# bcm2711_lpa register map
Vendor: BROADCOM; Series: BCM2711; File version: A
CPU: CA72 r0p0, little endian, MPU, FPU, 2 interrupt priority bits
Registers are 32-bit, read-write, reset 0x0 unless marked. A register's access mark holds for its fields unless they carry their own. Offsets are from the block's base; [hi:lo] are bit positions; lines under a group give offsets from that group; {n}, {i} and the like mark numbered series; 'fields as' and 'values as' point back to an identical list.

## GIC_DIST — ARM GIC-400 Generic Interrupt Controller Distributor
Base 0xFF841000
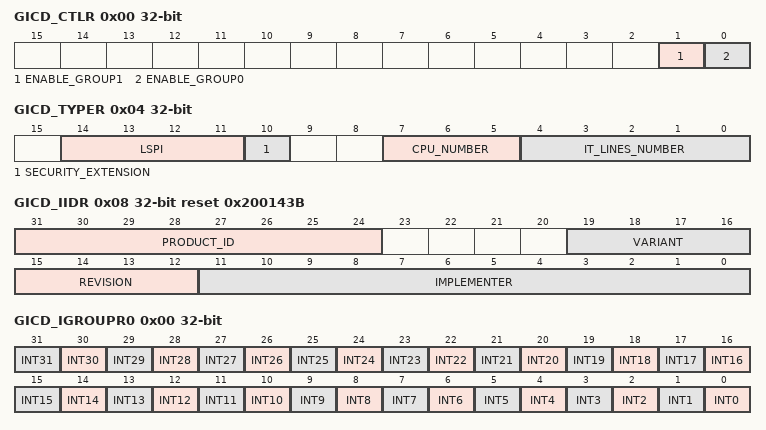
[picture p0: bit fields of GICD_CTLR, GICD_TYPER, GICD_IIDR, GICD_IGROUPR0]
0x00 GICD_CTLR — Distributor Control Register
  [1] ENABLE_GROUP1 — Enable group 1 interrupts
  [0] ENABLE_GROUP0 — Enable group 0 interrupts
0x04 GICD_TYPER ro — Interrupt Controller Type Register
  [14:11] LSPI — Lockable SPI count
  [10] SECURITY_EXTENSION — Security extension implemented
  [7:5] CPU_NUMBER
  [4:0] IT_LINES_NUMBER — Interrupt line number
0x08 GICD_IIDR ro reset 0x200143B — Distributor Implementer Identification Register
  [31:24] PRODUCT_ID, [19:16] VARIANT, [15:12] REVISION, [11:0] IMPLEMENTER
0x80 GICD_IGROUPR group — Interrupt Group Registers
  0x00 GICD_IGROUPR0 — Interrupt Group
    [n] INT{n} (n=0..31) — Interrupt {n}
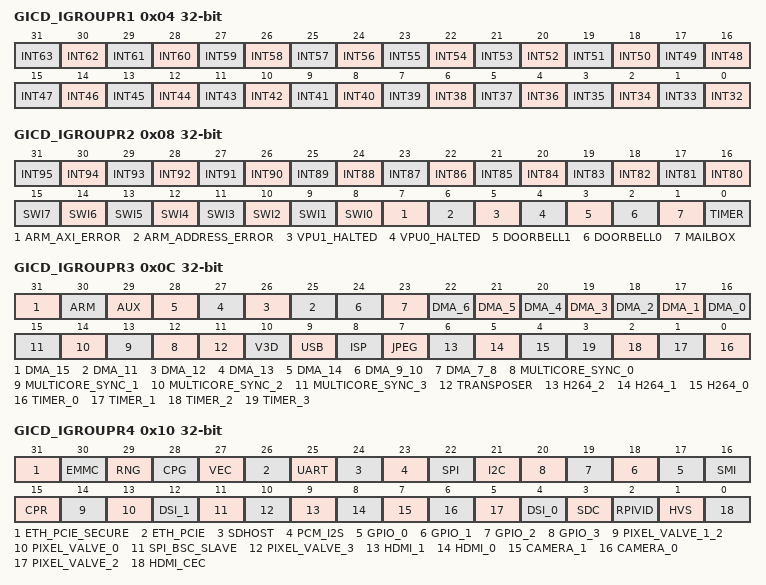
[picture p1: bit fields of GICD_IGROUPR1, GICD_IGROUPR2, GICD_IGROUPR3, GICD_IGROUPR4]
  0x04 GICD_IGROUPR1 — Interrupt Group
    [n-32] INT{n} (n=32..63) — Interrupt {n}
  0x08 GICD_IGROUPR2 — Interrupt Group
    [n-64] INT{n} (n=80..95) — Interrupt {n}
    [n+8] SWI{n} (n=0..7) — Software interrupt {n}
    [7] ARM_AXI_ERROR
    [6] ARM_ADDRESS_ERROR
    [5] VPU1_HALTED
    [4] VPU0_HALTED
    [3] DOORBELL1
    [2] DOORBELL0
    [1] MAILBOX
    [0] TIMER — ARMC Timer
  0x0C GICD_IGROUPR3 — Interrupt Group
    [31] DMA_15
    [30] ARM
    [29] AUX — OR of UART1, SPI1 and SPI2
    [n+14] DMA_{n} (n=11..14)
    [24] DMA_9_10 — OR of DMA 9 and 10
    [23] DMA_7_8 — OR of DMA 7 and 8
    [n+16] DMA_{n} (n=0..6)
    [n+12] MULTICORE_SYNC_{n} (n=0..3)
    [11] TRANSPOSER
    [10] V3D
    [9] USB
    [8] ISP
    [7] JPEG
    [6] H264_2
    [5] H264_1
    [4] H264_0
    [n] TIMER_{n} (n=0..3)
  0x10 GICD_IGROUPR4 — Interrupt Group
    [31] ETH_PCIE_SECURE
    [30] EMMC — OR of EMMC and EMMC2
    [29] RNG
    [28] CPG
    [27] VEC
    [26] ETH_PCIE — OR of all ETH_PCIe L2
    [25] UART — OR of all PL011 UARTs
    [24] SDHOST
    [23] PCM_I2S
    [22] SPI — OR of all SPI
    [21] I2C — OR of all I2C
    [n+17] GPIO_{n} (n=0..3)
    [16] SMI
    [15] CPR
    [14] PIXEL_VALVE_1_2 — OR of Pixel Valve 1 and 2
    [13] PIXEL_VALVE_0
    [12] DSI_1
    [11] SPI_BSC_SLAVE
    [10] PIXEL_VALVE_3
    [9] HDMI_1
    [8] HDMI_0
    [7] CAMERA_1
    [6] CAMERA_0
    [5] PIXEL_VALVE_2
    [4] DSI_0
    [3] SDC
    [2] RPIVID
    [1] HVS
    [0] HDMI_CEC
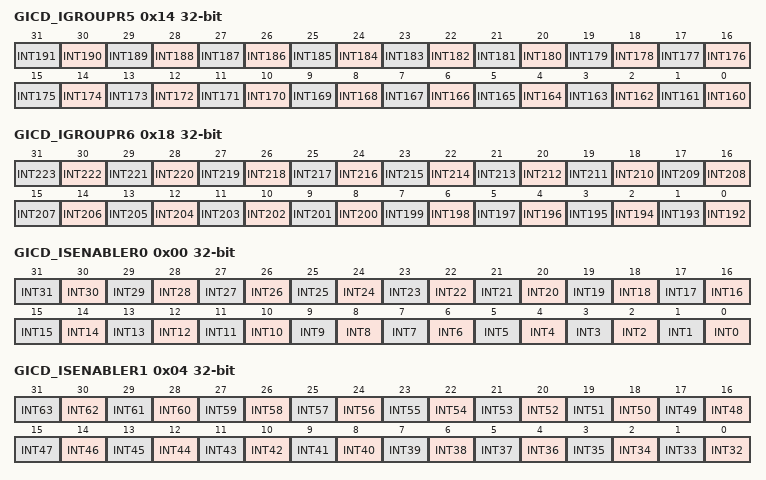
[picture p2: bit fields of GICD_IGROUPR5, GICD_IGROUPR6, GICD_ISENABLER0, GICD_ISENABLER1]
  0x14 GICD_IGROUPR5 — Interrupt Group
    [n-160] INT{n} (n=160..191) — Interrupt {n}
  0x18 GICD_IGROUPR6 — Interrupt Group
    [n-192] INT{n} (n=192..223) — Interrupt {n}
0x100 GICD_ISENABLER group — Interrupt Set-Enable Registers
  0x00 GICD_ISENABLER0 write-1-sets — Interrupt Set-Enable
    [n] INT{n} (n=0..31) — Interrupt {n}
  0x04 GICD_ISENABLER1 write-1-sets — Interrupt Set-Enable
    [n-32] INT{n} (n=32..63) — Interrupt {n}
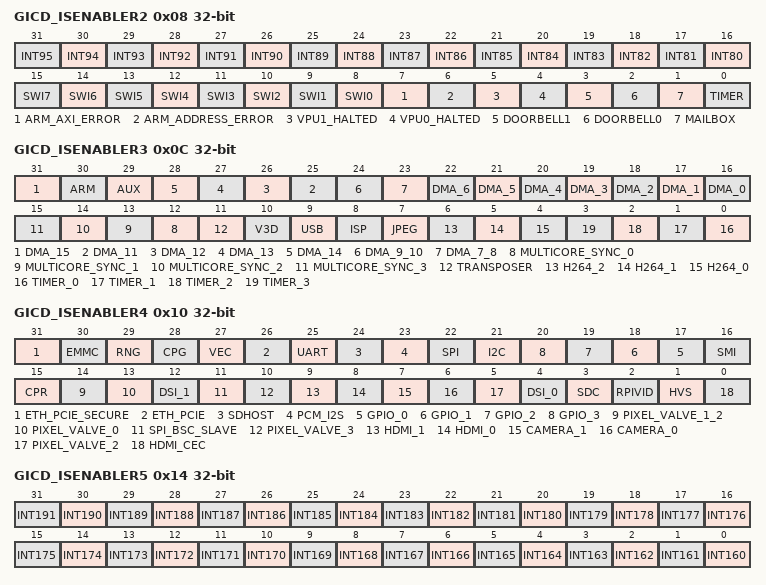
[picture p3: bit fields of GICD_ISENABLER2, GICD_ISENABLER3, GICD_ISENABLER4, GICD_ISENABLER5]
  0x08 GICD_ISENABLER2 write-1-sets — Interrupt Set-Enable
    fields as GICD_IGROUPR.GICD_IGROUPR2
  0x0C GICD_ISENABLER3 write-1-sets — Interrupt Set-Enable
    fields as GICD_IGROUPR.GICD_IGROUPR3
  0x10 GICD_ISENABLER4 write-1-sets — Interrupt Set-Enable
    fields as GICD_IGROUPR.GICD_IGROUPR4
  0x14 GICD_ISENABLER5 write-1-sets — Interrupt Set-Enable
    [n-160] INT{n} (n=160..191) — Interrupt {n}
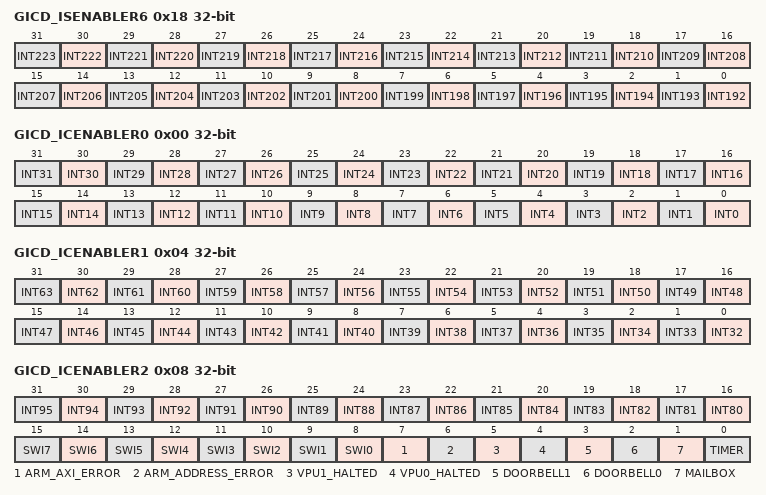
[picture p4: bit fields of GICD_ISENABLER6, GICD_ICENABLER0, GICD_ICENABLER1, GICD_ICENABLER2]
  0x18 GICD_ISENABLER6 write-1-sets — Interrupt Set-Enable
    [n-192] INT{n} (n=192..223) — Interrupt {n}
0x180 GICD_ICENABLER group — Interrupt Clear-Enable Registers
  0x00 GICD_ICENABLER0 write-1-clears — Interrupt Clear-Enable
    [n] INT{n} (n=0..31) — Interrupt {n}
  0x04 GICD_ICENABLER1 write-1-clears — Interrupt Clear-Enable
    [n-32] INT{n} (n=32..63) — Interrupt {n}
  0x08 GICD_ICENABLER2 write-1-clears — Interrupt Clear-Enable
    fields as GICD_IGROUPR.GICD_IGROUPR2
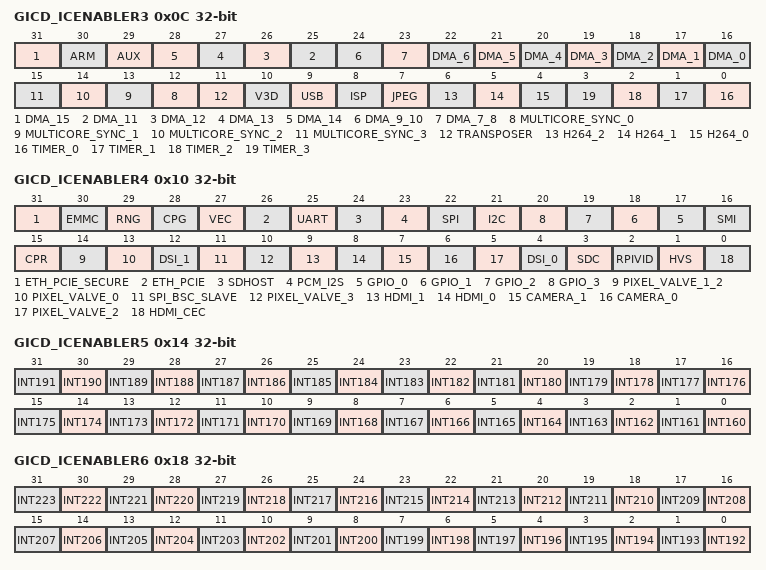
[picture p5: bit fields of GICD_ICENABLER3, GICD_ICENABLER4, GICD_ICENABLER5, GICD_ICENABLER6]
  0x0C GICD_ICENABLER3 write-1-clears — Interrupt Clear-Enable
    fields as GICD_IGROUPR.GICD_IGROUPR3
  0x10 GICD_ICENABLER4 write-1-clears — Interrupt Clear-Enable
    fields as GICD_IGROUPR.GICD_IGROUPR4
  0x14 GICD_ICENABLER5 write-1-clears — Interrupt Clear-Enable
    [n-160] INT{n} (n=160..191) — Interrupt {n}
  0x18 GICD_ICENABLER6 write-1-clears — Interrupt Clear-Enable
    [n-192] INT{n} (n=192..223) — Interrupt {n}
0x200 GICD_ISPENDR group — Interrupt Set-Pending Registers
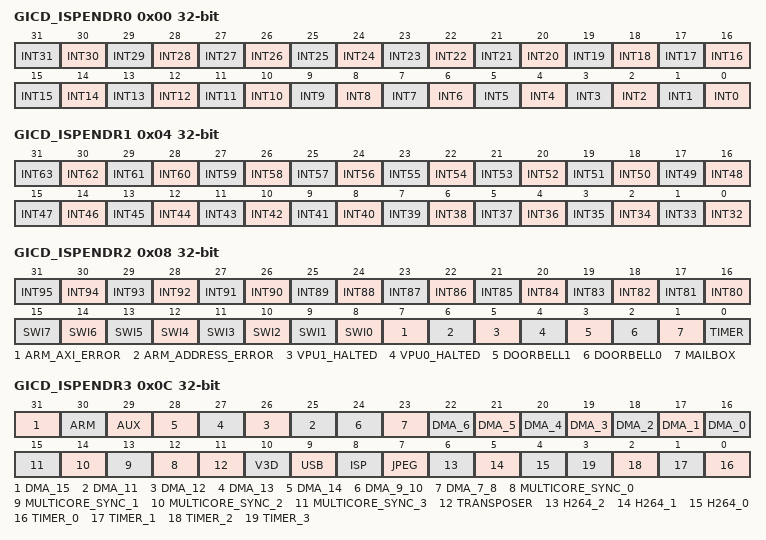
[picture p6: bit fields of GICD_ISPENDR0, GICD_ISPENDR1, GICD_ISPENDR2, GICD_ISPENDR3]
  0x00 GICD_ISPENDR0 write-1-sets — Interrupt Set-Pending
    [n] INT{n} (n=0..31) — Interrupt {n}
  0x04 GICD_ISPENDR1 write-1-sets — Interrupt Set-Pending
    [n-32] INT{n} (n=32..63) — Interrupt {n}
  0x08 GICD_ISPENDR2 write-1-sets — Interrupt Set-Pending
    fields as GICD_IGROUPR.GICD_IGROUPR2
  0x0C GICD_ISPENDR3 write-1-sets — Interrupt Set-Pending
    fields as GICD_IGROUPR.GICD_IGROUPR3
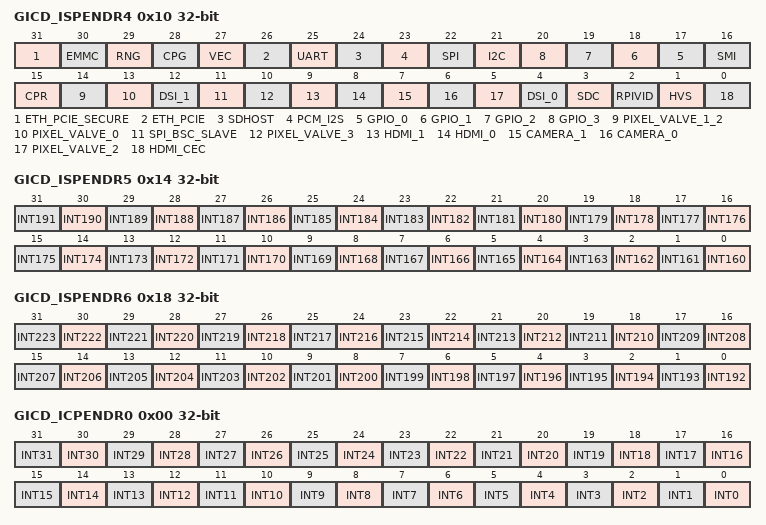
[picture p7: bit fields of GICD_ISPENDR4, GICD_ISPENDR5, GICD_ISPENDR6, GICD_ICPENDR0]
  0x10 GICD_ISPENDR4 write-1-sets — Interrupt Set-Pending
    fields as GICD_IGROUPR.GICD_IGROUPR4
  0x14 GICD_ISPENDR5 write-1-sets — Interrupt Set-Pending
    [n-160] INT{n} (n=160..191) — Interrupt {n}
  0x18 GICD_ISPENDR6 write-1-sets — Interrupt Set-Pending
    [n-192] INT{n} (n=192..223) — Interrupt {n}
0x280 GICD_ICPENDR group — Interrupt Clear-Pending Registers
  0x00 GICD_ICPENDR0 write-1-clears — Interrupt Clear-Pending
    [n] INT{n} (n=0..31) — Interrupt {n}
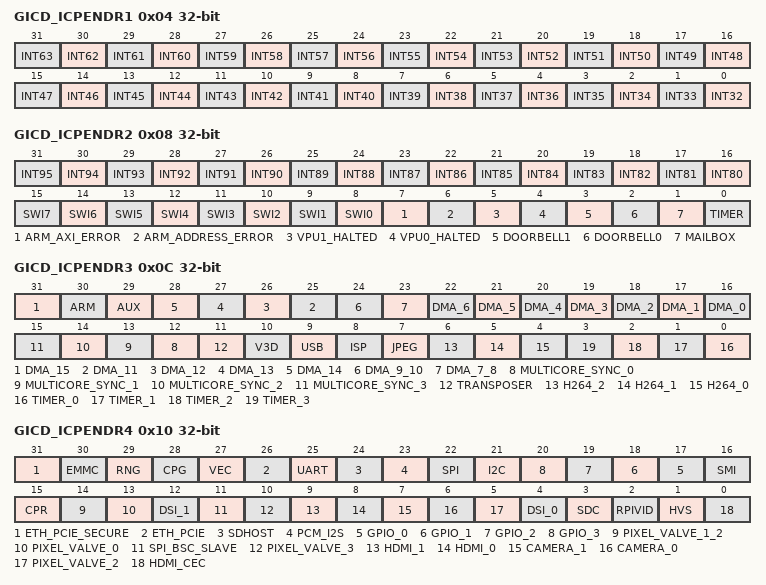
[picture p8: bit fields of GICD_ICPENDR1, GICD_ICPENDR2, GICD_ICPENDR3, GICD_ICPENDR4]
  0x04 GICD_ICPENDR1 write-1-clears — Interrupt Clear-Pending
    [n-32] INT{n} (n=32..63) — Interrupt {n}
  0x08 GICD_ICPENDR2 write-1-clears — Interrupt Clear-Pending
    fields as GICD_IGROUPR.GICD_IGROUPR2
  0x0C GICD_ICPENDR3 write-1-clears — Interrupt Clear-Pending
    fields as GICD_IGROUPR.GICD_IGROUPR3
  0x10 GICD_ICPENDR4 write-1-clears — Interrupt Clear-Pending
    fields as GICD_IGROUPR.GICD_IGROUPR4
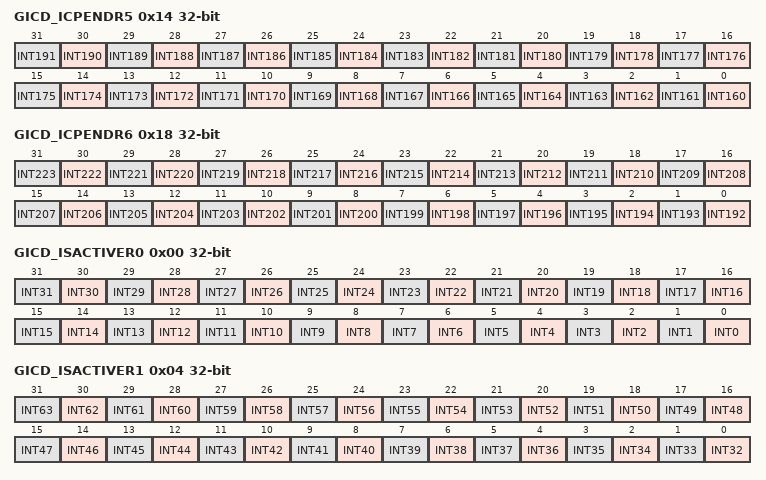
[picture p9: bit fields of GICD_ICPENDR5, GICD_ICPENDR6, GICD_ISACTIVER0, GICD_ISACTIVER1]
  0x14 GICD_ICPENDR5 write-1-clears — Interrupt Clear-Pending
    [n-160] INT{n} (n=160..191) — Interrupt {n}
  0x18 GICD_ICPENDR6 write-1-clears — Interrupt Clear-Pending
    [n-192] INT{n} (n=192..223) — Interrupt {n}
0x300 GICD_ISACTIVER group — Interrupt Set-Active Registers
  0x00 GICD_ISACTIVER0 write-1-sets — Interrupt Set-Active
    [n] INT{n} (n=0..31) — Interrupt {n}
  0x04 GICD_ISACTIVER1 write-1-sets — Interrupt Set-Active
    [n-32] INT{n} (n=32..63) — Interrupt {n}
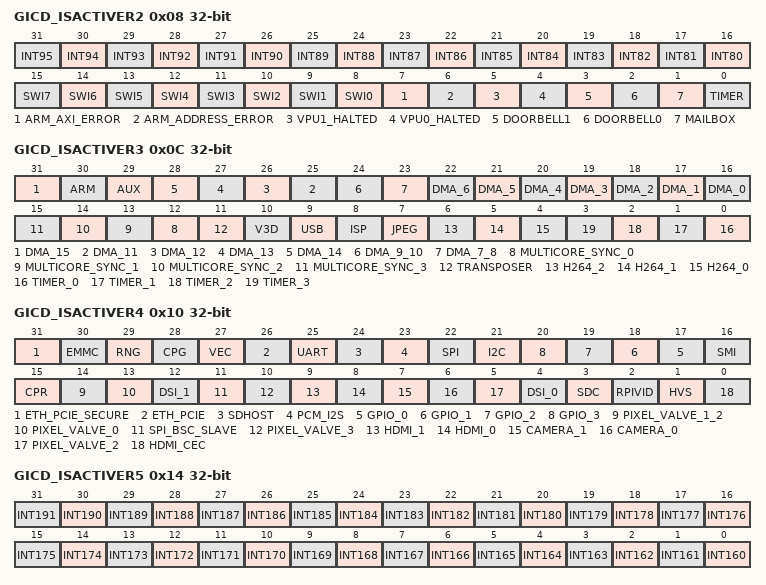
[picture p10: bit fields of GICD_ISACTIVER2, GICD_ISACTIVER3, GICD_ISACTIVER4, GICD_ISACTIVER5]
  0x08 GICD_ISACTIVER2 write-1-sets — Interrupt Set-Active
    fields as GICD_IGROUPR.GICD_IGROUPR2
  0x0C GICD_ISACTIVER3 write-1-sets — Interrupt Set-Active
    fields as GICD_IGROUPR.GICD_IGROUPR3
  0x10 GICD_ISACTIVER4 write-1-sets — Interrupt Set-Active
    fields as GICD_IGROUPR.GICD_IGROUPR4
  0x14 GICD_ISACTIVER5 write-1-sets — Interrupt Set-Active
    [n-160] INT{n} (n=160..191) — Interrupt {n}
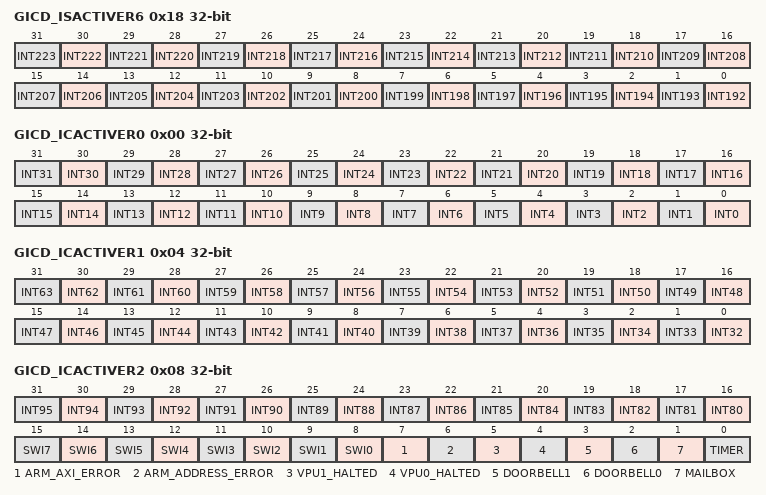
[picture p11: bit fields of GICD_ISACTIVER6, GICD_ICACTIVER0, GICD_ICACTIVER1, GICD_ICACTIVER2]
  0x18 GICD_ISACTIVER6 write-1-sets — Interrupt Set-Active
    [n-192] INT{n} (n=192..223) — Interrupt {n}
0x380 GICD_ICACTIVER group — Interrupt Clear-Active Registers
  0x00 GICD_ICACTIVER0 write-1-clears — Interrupt Clear-Active
    [n] INT{n} (n=0..31) — Interrupt {n}
  0x04 GICD_ICACTIVER1 write-1-clears — Interrupt Clear-Active
    [n-32] INT{n} (n=32..63) — Interrupt {n}
  0x08 GICD_ICACTIVER2 write-1-clears — Interrupt Clear-Active
    fields as GICD_IGROUPR.GICD_IGROUPR2
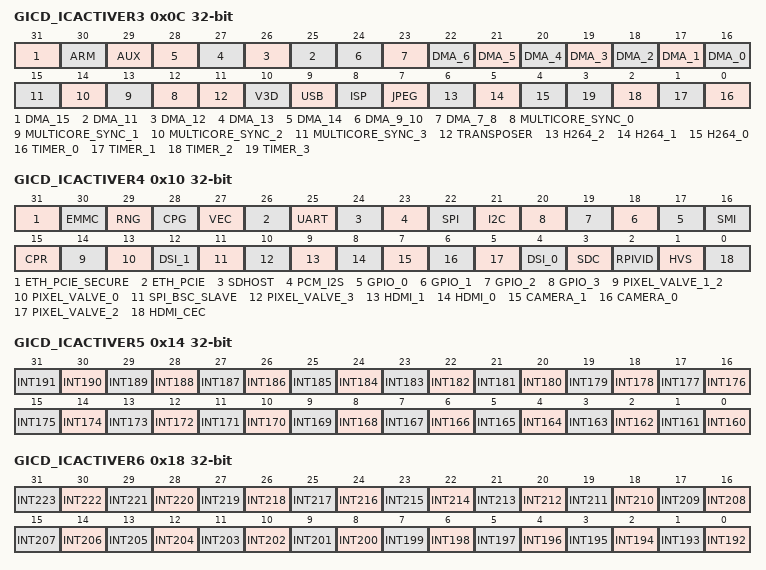
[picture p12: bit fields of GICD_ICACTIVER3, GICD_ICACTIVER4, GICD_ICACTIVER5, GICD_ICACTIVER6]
  0x0C GICD_ICACTIVER3 write-1-clears — Interrupt Clear-Active
    fields as GICD_IGROUPR.GICD_IGROUPR3
  0x10 GICD_ICACTIVER4 write-1-clears — Interrupt Clear-Active
    fields as GICD_IGROUPR.GICD_IGROUPR4
  0x14 GICD_ICACTIVER5 write-1-clears — Interrupt Clear-Active
    [n-160] INT{n} (n=160..191) — Interrupt {n}
  0x18 GICD_ICACTIVER6 write-1-clears — Interrupt Clear-Active
    [n-192] INT{n} (n=192..223) — Interrupt {n}
0x400 GICD_IPRIORITYR group — Interrupt Priority
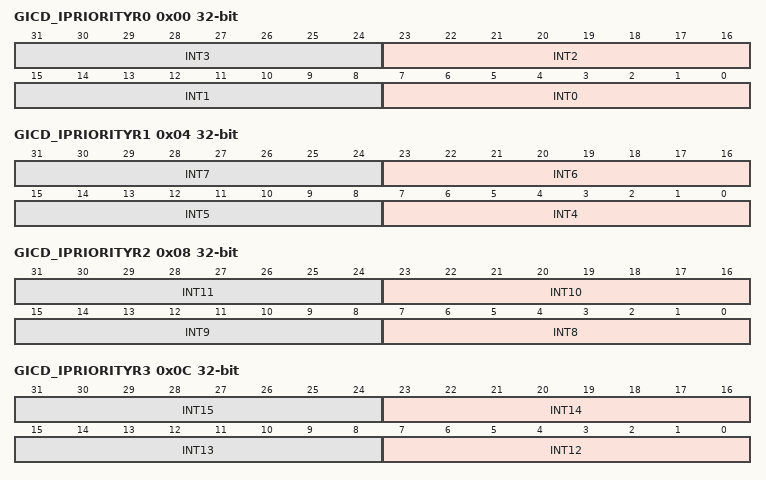
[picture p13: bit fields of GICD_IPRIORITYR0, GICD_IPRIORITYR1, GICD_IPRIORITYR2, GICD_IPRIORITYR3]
  0x00 GICD_IPRIORITYR0 — Interrupt Priority 0 - 3 (Lower is first)
    [8n+7:8n] INT{n} (n=0..3) — Interrupt {n}
  0x04 GICD_IPRIORITYR1 — Interrupt Priority 4 - 7 (Lower is first)
    [8n-25:8n-32] INT{n} (n=4..7) — Interrupt {n}
  0x08 GICD_IPRIORITYR2 — Interrupt Priority 8 - 11 (Lower is first)
    [8n-57:8n-64] INT{n} (n=8..11) — Interrupt {n}
  0x0C GICD_IPRIORITYR3 — Interrupt Priority 12 - 15 (Lower is first)
    [8n-89:8n-96] INT{n} (n=12..15) — Interrupt {n}
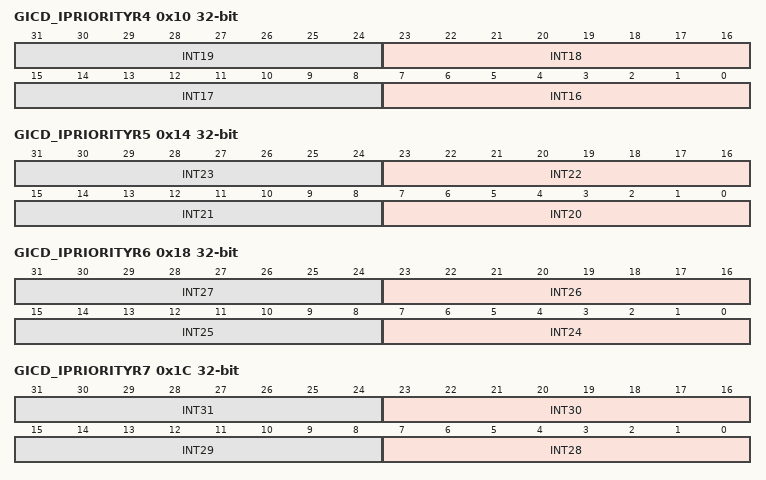
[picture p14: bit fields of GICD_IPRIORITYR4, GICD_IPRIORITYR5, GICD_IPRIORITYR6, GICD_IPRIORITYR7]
  0x10 GICD_IPRIORITYR4 — Interrupt Priority 16 - 19 (Lower is first)
    [8n-121:8n-128] INT{n} (n=16..19) — Interrupt {n}
  0x14 GICD_IPRIORITYR5 — Interrupt Priority 20 - 23 (Lower is first)
    [8n-153:8n-160] INT{n} (n=20..23) — Interrupt {n}
  0x18 GICD_IPRIORITYR6 — Interrupt Priority 24 - 27 (Lower is first)
    [8n-185:8n-192] INT{n} (n=24..27) — Interrupt {n}
  0x1C GICD_IPRIORITYR7 — Interrupt Priority 28 - 31 (Lower is first)
    [8n-217:8n-224] INT{n} (n=28..31) — Interrupt {n}
  0x20 GICD_IPRIORITYR8 — Interrupt Priority 32 - 35 (Lower is first)
    [8n-249:8n-256] INT{n} (n=32..35) — Interrupt {n}
  0x24 GICD_IPRIORITYR9 — Interrupt Priority 36 - 39 (Lower is first)
    [8n-281:8n-288] INT{n} (n=36..39) — Interrupt {n}
  0x28 GICD_IPRIORITYR10 — Interrupt Priority 40 - 43 (Lower is first)
    [8n-313:8n-320] INT{n} (n=40..43) — Interrupt {n}
  0x2C GICD_IPRIORITYR11 — Interrupt Priority 44 - 47 (Lower is first)
    [8n-345:8n-352] INT{n} (n=44..47) — Interrupt {n}
  0x30 GICD_IPRIORITYR12 — Interrupt Priority 48 - 51 (Lower is first)
    [8n-377:8n-384] INT{n} (n=48..51) — Interrupt {n}
  0x34 GICD_IPRIORITYR13 — Interrupt Priority 52 - 55 (Lower is first)
    [8n-409:8n-416] INT{n} (n=52..55) — Interrupt {n}
  0x38 GICD_IPRIORITYR14 — Interrupt Priority 56 - 59 (Lower is first)
    [8n-441:8n-448] INT{n} (n=56..59) — Interrupt {n}
  0x3C GICD_IPRIORITYR15 — Interrupt Priority 60 - 63 (Lower is first)
    [8n-473:8n-480] INT{n} (n=60..63) — Interrupt {n}
  0x40 GICD_IPRIORITYR16 — Interrupt Priority 64 - 67 (Lower is first)
    [31:24] DOORBELL1
    [23:16] DOORBELL0
    [15:8] MAILBOX
    [7:0] TIMER — ARMC Timer
  0x44 GICD_IPRIORITYR17 — Interrupt Priority 68 - 71 (Lower is first)
    [31:24] ARM_AXI_ERROR, [23:16] ARM_ADDRESS_ERROR, [15:8] VPU1_HALTED, [7:0] VPU0_HALTED
  0x48 GICD_IPRIORITYR18 — Interrupt Priority 72 - 75 (Lower is first)
    [8n+7:8n] SWI{n} (n=0..3) — Software interrupt {n}
  0x4C GICD_IPRIORITYR19 — Interrupt Priority 76 - 79 (Lower is first)
    [8n-25:8n-32] SWI{n} (n=4..7) — Software interrupt {n}
  0x50 GICD_IPRIORITYR20 — Interrupt Priority 80 - 83 (Lower is first)
    [8n-633:8n-640] INT{n} (n=80..83) — Interrupt {n}
  0x54 GICD_IPRIORITYR21 — Interrupt Priority 84 - 87 (Lower is first)
    [8n-665:8n-672] INT{n} (n=84..87) — Interrupt {n}
  0x58 GICD_IPRIORITYR22 — Interrupt Priority 88 - 91 (Lower is first)
    [8n-697:8n-704] INT{n} (n=88..91) — Interrupt {n}
  0x5C GICD_IPRIORITYR23 — Interrupt Priority 92 - 95 (Lower is first)
    [8n-729:8n-736] INT{n} (n=92..95) — Interrupt {n}
  0x60 GICD_IPRIORITYR24 — Interrupt Priority 96 - 99 (Lower is first)
    [8n+7:8n] TIMER_{n} (n=0..3)
  0x64 GICD_IPRIORITYR25 — Interrupt Priority 100 - 103 (Lower is first)
    [31:24] JPEG, [23:16] H264_2, [15:8] H264_1, [7:0] H264_0
  0x68 GICD_IPRIORITYR26 — Interrupt Priority 104 - 107 (Lower is first)
    [31:24] TRANSPOSER, [23:16] V3D, [15:8] USB, [7:0] ISP
  0x6C GICD_IPRIORITYR27 — Interrupt Priority 108 - 111 (Lower is first)
    [8n+7:8n] MULTICORE_SYNC_{n} (n=0..3)
  0x70 GICD_IPRIORITYR28 — Interrupt Priority 112 - 115 (Lower is first)
    [8n+7:8n] DMA_{n} (n=0..3)
  0x74 GICD_IPRIORITYR29 — Interrupt Priority 116 - 119 (Lower is first)
    [31:24] DMA_7_8 — OR of DMA 7 and 8
    [23:16] DMA_6
    [15:8] DMA_5
    [7:0] DMA_4
  0x78 GICD_IPRIORITYR30 — Interrupt Priority 120 - 123 (Lower is first)
    [31:24] DMA_13
    [23:16] DMA_12
    [15:8] DMA_11
    [7:0] DMA_9_10 — OR of DMA 9 and 10
  0x7C GICD_IPRIORITYR31 — Interrupt Priority 124 - 127 (Lower is first)
    [31:24] DMA_15
    [23:16] ARM
    [15:8] AUX — OR of UART1, SPI1 and SPI2
    [7:0] DMA_14
  0x80 GICD_IPRIORITYR32 — Interrupt Priority 128 - 131 (Lower is first)
    [31:24] SDC, [23:16] RPIVID, [15:8] HVS, [7:0] HDMI_CEC
  0x84 GICD_IPRIORITYR33 — Interrupt Priority 132 - 135 (Lower is first)
    [31:24] CAMERA_1, [23:16] CAMERA_0, [15:8] PIXEL_VALVE_2, [7:0] DSI_0
  0x88 GICD_IPRIORITYR34 — Interrupt Priority 136 - 139 (Lower is first)
    [31:24] SPI_BSC_SLAVE, [23:16] PIXEL_VALVE_3, [15:8] HDMI_1, [7:0] HDMI_0
  0x8C GICD_IPRIORITYR35 — Interrupt Priority 140 - 143 (Lower is first)
    [31:24] CPR
    [23:16] PIXEL_VALVE_1_2 — OR of Pixel Valve 1 and 2
    [15:8] PIXEL_VALVE_0
    [7:0] DSI_1
  0x90 GICD_IPRIORITYR36 — Interrupt Priority 144 - 147 (Lower is first)
    [31:24] GPIO_2, [23:16] GPIO_1, [15:8] GPIO_0, [7:0] SMI
  0x94 GICD_IPRIORITYR37 — Interrupt Priority 148 - 151 (Lower is first)
    [31:24] PCM_I2S
    [23:16] SPI — OR of all SPI
    [15:8] I2C — OR of all I2C
    [7:0] GPIO_3
  0x98 GICD_IPRIORITYR38 — Interrupt Priority 152 - 155 (Lower is first)
    [31:24] VEC
    [23:16] ETH_PCIE — OR of all ETH_PCIe L2
    [15:8] UART — OR of all PL011 UARTs
    [7:0] SDHOST
  0x9C GICD_IPRIORITYR39 — Interrupt Priority 156 - 159 (Lower is first)
    [31:24] ETH_PCIE_SECURE
    [23:16] EMMC — OR of EMMC and EMMC2
    [15:8] RNG
    [7:0] CPG
  0xA0 GICD_IPRIORITYR40 — Interrupt Priority 160 - 163 (Lower is first)
    [8n-1273:8n-1280] INT{n} (n=160..163) — Interrupt {n}
  0xA4 GICD_IPRIORITYR41 — Interrupt Priority 164 - 167 (Lower is first)
    [8n-1305:8n-1312] INT{n} (n=164..167) — Interrupt {n}
  0xA8 GICD_IPRIORITYR42 — Interrupt Priority 168 - 171 (Lower is first)
    [8n-1337:8n-1344] INT{n} (n=168..171) — Interrupt {n}
  0xAC GICD_IPRIORITYR43 — Interrupt Priority 172 - 175 (Lower is first)
    [8n-1369:8n-1376] INT{n} (n=172..175) — Interrupt {n}
  0xB0 GICD_IPRIORITYR44 — Interrupt Priority 176 - 179 (Lower is first)
    [8n-1401:8n-1408] INT{n} (n=176..179) — Interrupt {n}
  0xB4 GICD_IPRIORITYR45 — Interrupt Priority 180 - 183 (Lower is first)
    [8n-1433:8n-1440] INT{n} (n=180..183) — Interrupt {n}
  0xB8 GICD_IPRIORITYR46 — Interrupt Priority 184 - 187 (Lower is first)
    [8n-1465:8n-1472] INT{n} (n=184..187) — Interrupt {n}
  0xBC GICD_IPRIORITYR47 — Interrupt Priority 188 - 191 (Lower is first)
    [8n-1497:8n-1504] INT{n} (n=188..191) — Interrupt {n}
  0xC0 GICD_IPRIORITYR48 — Interrupt Priority 192 - 195 (Lower is first)
    [8n-1529:8n-1536] INT{n} (n=192..195) — Interrupt {n}
  0xC4 GICD_IPRIORITYR49 — Interrupt Priority 196 - 199 (Lower is first)
    [8n-1561:8n-1568] INT{n} (n=196..199) — Interrupt {n}
  0xC8 GICD_IPRIORITYR50 — Interrupt Priority 200 - 203 (Lower is first)
    [8n-1593:8n-1600] INT{n} (n=200..203) — Interrupt {n}
  0xCC GICD_IPRIORITYR51 — Interrupt Priority 204 - 207 (Lower is first)
    [8n-1625:8n-1632] INT{n} (n=204..207) — Interrupt {n}
  0xD0 GICD_IPRIORITYR52 — Interrupt Priority 208 - 211 (Lower is first)
    [8n-1657:8n-1664] INT{n} (n=208..211) — Interrupt {n}
  0xD4 GICD_IPRIORITYR53 — Interrupt Priority 212 - 215 (Lower is first)
    [8n-1689:8n-1696] INT{n} (n=212..215) — Interrupt {n}
  0xD8 GICD_IPRIORITYR54 — Interrupt Priority 216 - 219 (Lower is first)
    [8n-1721:8n-1728] INT{n} (n=216..219) — Interrupt {n}
  0xDC GICD_IPRIORITYR55 — Interrupt Priority 220 - 223 (Lower is first)
    [8n-1753:8n-1760] INT{n} (n=220..223) — Interrupt {n}
0x800 GICD_ITARGETSR group — Interrupt Processor Targets
  0x00 GICD_ITARGETSR0 — Interrupt Processor Target 0 - 3
    [8n+7:8n] INT{n} (n=0..3) — Interrupt {n}
  0x04 GICD_ITARGETSR1 — Interrupt Processor Target 4 - 7
    [8n-25:8n-32] INT{n} (n=4..7) — Interrupt {n}
  0x08 GICD_ITARGETSR2 — Interrupt Processor Target 8 - 11
    [8n-57:8n-64] INT{n} (n=8..11) — Interrupt {n}
  0x0C GICD_ITARGETSR3 — Interrupt Processor Target 12 - 15
    [8n-89:8n-96] INT{n} (n=12..15) — Interrupt {n}
  0x10 GICD_ITARGETSR4 — Interrupt Processor Target 16 - 19
    [8n-121:8n-128] INT{n} (n=16..19) — Interrupt {n}
  0x14 GICD_ITARGETSR5 — Interrupt Processor Target 20 - 23
    [8n-153:8n-160] INT{n} (n=20..23) — Interrupt {n}
  0x18 GICD_ITARGETSR6 — Interrupt Processor Target 24 - 27
    [8n-185:8n-192] INT{n} (n=24..27) — Interrupt {n}
  0x1C GICD_ITARGETSR7 — Interrupt Processor Target 28 - 31
    [8n-217:8n-224] INT{n} (n=28..31) — Interrupt {n}
  0x20 GICD_ITARGETSR8 — Interrupt Processor Target 32 - 35
    [8n-249:8n-256] INT{n} (n=32..35) — Interrupt {n}
  0x24 GICD_ITARGETSR9 — Interrupt Processor Target 36 - 39
    [8n-281:8n-288] INT{n} (n=36..39) — Interrupt {n}
  0x28 GICD_ITARGETSR10 — Interrupt Processor Target 40 - 43
    [8n-313:8n-320] INT{n} (n=40..43) — Interrupt {n}
  0x2C GICD_ITARGETSR11 — Interrupt Processor Target 44 - 47
    [8n-345:8n-352] INT{n} (n=44..47) — Interrupt {n}
  0x30 GICD_ITARGETSR12 — Interrupt Processor Target 48 - 51
    [8n-377:8n-384] INT{n} (n=48..51) — Interrupt {n}
  0x34 GICD_ITARGETSR13 — Interrupt Processor Target 52 - 55
    [8n-409:8n-416] INT{n} (n=52..55) — Interrupt {n}
  0x38 GICD_ITARGETSR14 — Interrupt Processor Target 56 - 59
    [8n-441:8n-448] INT{n} (n=56..59) — Interrupt {n}
  0x3C GICD_ITARGETSR15 — Interrupt Processor Target 60 - 63
    [8n-473:8n-480] INT{n} (n=60..63) — Interrupt {n}
  0x40 GICD_ITARGETSR16 — Interrupt Processor Target 64 - 67
    fields as GICD_IPRIORITYR.GICD_IPRIORITYR16
  0x44 GICD_ITARGETSR17 — Interrupt Processor Target 68 - 71
    fields as GICD_IPRIORITYR.GICD_IPRIORITYR17
  0x48 GICD_ITARGETSR18 — Interrupt Processor Target 72 - 75
    [8n+7:8n] SWI{n} (n=0..3) — Software interrupt {n}
  0x4C GICD_ITARGETSR19 — Interrupt Processor Target 76 - 79
    [8n-25:8n-32] SWI{n} (n=4..7) — Software interrupt {n}
  0x50 GICD_ITARGETSR20 — Interrupt Processor Target 80 - 83
    [8n-633:8n-640] INT{n} (n=80..83) — Interrupt {n}
  0x54 GICD_ITARGETSR21 — Interrupt Processor Target 84 - 87
    [8n-665:8n-672] INT{n} (n=84..87) — Interrupt {n}
  0x58 GICD_ITARGETSR22 — Interrupt Processor Target 88 - 91
    [8n-697:8n-704] INT{n} (n=88..91) — Interrupt {n}
  0x5C GICD_ITARGETSR23 — Interrupt Processor Target 92 - 95
    [8n-729:8n-736] INT{n} (n=92..95) — Interrupt {n}
  0x60 GICD_ITARGETSR24 — Interrupt Processor Target 96 - 99
    [8n+7:8n] TIMER_{n} (n=0..3)
  0x64 GICD_ITARGETSR25 — Interrupt Processor Target 100 - 103
    [31:24] JPEG, [23:16] H264_2, [15:8] H264_1, [7:0] H264_0
  0x68 GICD_ITARGETSR26 — Interrupt Processor Target 104 - 107
    [31:24] TRANSPOSER, [23:16] V3D, [15:8] USB, [7:0] ISP
  0x6C GICD_ITARGETSR27 — Interrupt Processor Target 108 - 111
    [8n+7:8n] MULTICORE_SYNC_{n} (n=0..3)
  0x70 GICD_ITARGETSR28 — Interrupt Processor Target 112 - 115
    [8n+7:8n] DMA_{n} (n=0..3)
  0x74 GICD_ITARGETSR29 — Interrupt Processor Target 116 - 119
    fields as GICD_IPRIORITYR.GICD_IPRIORITYR29
  0x78 GICD_ITARGETSR30 — Interrupt Processor Target 120 - 123
    fields as GICD_IPRIORITYR.GICD_IPRIORITYR30
  0x7C GICD_ITARGETSR31 — Interrupt Processor Target 124 - 127
    fields as GICD_IPRIORITYR.GICD_IPRIORITYR31
  0x80 GICD_ITARGETSR32 — Interrupt Processor Target 128 - 131
    [31:24] SDC, [23:16] RPIVID, [15:8] HVS, [7:0] HDMI_CEC
  0x84 GICD_ITARGETSR33 — Interrupt Processor Target 132 - 135
    fields as GICD_IPRIORITYR.GICD_IPRIORITYR33
  0x88 GICD_ITARGETSR34 — Interrupt Processor Target 136 - 139
    fields as GICD_IPRIORITYR.GICD_IPRIORITYR34
  0x8C GICD_ITARGETSR35 — Interrupt Processor Target 140 - 143
    fields as GICD_IPRIORITYR.GICD_IPRIORITYR35
  0x90 GICD_ITARGETSR36 — Interrupt Processor Target 144 - 147
    [31:24] GPIO_2, [23:16] GPIO_1, [15:8] GPIO_0, [7:0] SMI
  0x94 GICD_ITARGETSR37 — Interrupt Processor Target 148 - 151
    fields as GICD_IPRIORITYR.GICD_IPRIORITYR37
  0x98 GICD_ITARGETSR38 — Interrupt Processor Target 152 - 155
    fields as GICD_IPRIORITYR.GICD_IPRIORITYR38
  0x9C GICD_ITARGETSR39 — Interrupt Processor Target 156 - 159
    fields as GICD_IPRIORITYR.GICD_IPRIORITYR39
  0xA0 GICD_ITARGETSR40 — Interrupt Processor Target 160 - 163
    [8n-1273:8n-1280] INT{n} (n=160..163) — Interrupt {n}
  0xA4 GICD_ITARGETSR41 — Interrupt Processor Target 164 - 167
    [8n-1305:8n-1312] INT{n} (n=164..167) — Interrupt {n}
  0xA8 GICD_ITARGETSR42 — Interrupt Processor Target 168 - 171
    [8n-1337:8n-1344] INT{n} (n=168..171) — Interrupt {n}
  0xAC GICD_ITARGETSR43 — Interrupt Processor Target 172 - 175
    [8n-1369:8n-1376] INT{n} (n=172..175) — Interrupt {n}
  0xB0 GICD_ITARGETSR44 — Interrupt Processor Target 176 - 179
    [8n-1401:8n-1408] INT{n} (n=176..179) — Interrupt {n}
  0xB4 GICD_ITARGETSR45 — Interrupt Processor Target 180 - 183
    [8n-1433:8n-1440] INT{n} (n=180..183) — Interrupt {n}
  0xB8 GICD_ITARGETSR46 — Interrupt Processor Target 184 - 187
    [8n-1465:8n-1472] INT{n} (n=184..187) — Interrupt {n}
  0xBC GICD_ITARGETSR47 — Interrupt Processor Target 188 - 191
    [8n-1497:8n-1504] INT{n} (n=188..191) — Interrupt {n}
  0xC0 GICD_ITARGETSR48 — Interrupt Processor Target 192 - 195
    [8n-1529:8n-1536] INT{n} (n=192..195) — Interrupt {n}
  0xC4 GICD_ITARGETSR49 — Interrupt Processor Target 196 - 199
    [8n-1561:8n-1568] INT{n} (n=196..199) — Interrupt {n}
  0xC8 GICD_ITARGETSR50 — Interrupt Processor Target 200 - 203
    [8n-1593:8n-1600] INT{n} (n=200..203) — Interrupt {n}
  0xCC GICD_ITARGETSR51 — Interrupt Processor Target 204 - 207
    [8n-1625:8n-1632] INT{n} (n=204..207) — Interrupt {n}
  0xD0 GICD_ITARGETSR52 — Interrupt Processor Target 208 - 211
    [8n-1657:8n-1664] INT{n} (n=208..211) — Interrupt {n}
  0xD4 GICD_ITARGETSR53 — Interrupt Processor Target 212 - 215
    [8n-1689:8n-1696] INT{n} (n=212..215) — Interrupt {n}
  0xD8 GICD_ITARGETSR54 — Interrupt Processor Target 216 - 219
    [8n-1721:8n-1728] INT{n} (n=216..219) — Interrupt {n}
  0xDC GICD_ITARGETSR55 — Interrupt Processor Target 220 - 223
    [8n-1753:8n-1760] INT{n} (n=220..223) — Interrupt {n}
0xC00 GICD_ICFGR group — Interrupt Configuration
  0x00 GICD_ICFGR0 — Interrupt Configuration 0 - 15
    [all] fields
      0=LEVEL (Level sensitive); 1=EDGE (Edge triggered)
    [2n+1] INT{n} (n=0..15) — Interrupt {n}
  0x04 GICD_ICFGR4 — Interrupt Configuration 16 - 31
    [all] fields
      0=LEVEL (Level sensitive); 1=EDGE (Edge triggered)
    [2n-31] INT{n} (n=16..31) — Interrupt {n}
  0x08 GICD_ICFGR8 — Interrupt Configuration 32 - 47
    [all] fields
      0=LEVEL (Level sensitive); 1=EDGE (Edge triggered)
    [2n-63] INT{n} (n=32..47) — Interrupt {n}
  0x0C GICD_ICFGR12 — Interrupt Configuration 48 - 63
    [all] fields
      0=LEVEL (Level sensitive); 1=EDGE (Edge triggered)
    [2n-95] INT{n} (n=48..63) — Interrupt {n}
  0x10 GICD_ICFGR16 — Interrupt Configuration 64 - 79
    [all] fields
      0=LEVEL (Level sensitive); 1=EDGE (Edge triggered)
    [2n+17] SWI{n} (n=0..7) — Software interrupt {n}
    [15] ARM_AXI_ERROR
    [13] ARM_ADDRESS_ERROR
    [11] VPU1_HALTED
    [9] VPU0_HALTED
    [7] DOORBELL1
    [5] DOORBELL0
    [3] MAILBOX
    [1] TIMER — ARMC Timer
  0x14 GICD_ICFGR20 — Interrupt Configuration 80 - 95
    [all] fields
      0=LEVEL (Level sensitive); 1=EDGE (Edge triggered)
    [2n-159] INT{n} (n=80..95) — Interrupt {n}
  0x18 GICD_ICFGR24 — Interrupt Configuration 96 - 111
    [all] fields
      0=LEVEL (Level sensitive); 1=EDGE (Edge triggered)
    [2n+25] MULTICORE_SYNC_{n} (n=0..3)
    [23] TRANSPOSER
    [21] V3D
    [19] USB
    [17] ISP
    [15] JPEG
    [13] H264_2
    [11] H264_1
    [9] H264_0
    [2n+1] TIMER_{n} (n=0..3)
  0x1C GICD_ICFGR28 — Interrupt Configuration 112 - 127
    [all] fields
      0=LEVEL (Level sensitive); 1=EDGE (Edge triggered)
    [31] DMA_15
    [29] ARM
    [27] AUX — OR of UART1, SPI1 and SPI2
    [2n-3] DMA_{n} (n=11..14)
    [17] DMA_9_10 — OR of DMA 9 and 10
    [15] DMA_7_8 — OR of DMA 7 and 8
    [2n+1] DMA_{n} (n=0..6)
  0x20 GICD_ICFGR32 — Interrupt Configuration 128 - 143
    [all] fields
      0=LEVEL (Level sensitive); 1=EDGE (Edge triggered)
    [31] CPR
    [29] PIXEL_VALVE_1_2 — OR of Pixel Valve 1 and 2
    [27] PIXEL_VALVE_0
    [25] DSI_1
    [23] SPI_BSC_SLAVE
    [21] PIXEL_VALVE_3
    [19] HDMI_1
    [17] HDMI_0
    [15] CAMERA_1
    [13] CAMERA_0
    [11] PIXEL_VALVE_2
    [9] DSI_0
    [7] SDC
    [5] RPIVID
    [3] HVS
    [1] HDMI_CEC
  0x24 GICD_ICFGR36 — Interrupt Configuration 144 - 159
    [all] fields
      0=LEVEL (Level sensitive); 1=EDGE (Edge triggered)
    [31] ETH_PCIE_SECURE
    [29] EMMC — OR of EMMC and EMMC2
    [27] RNG
    [25] CPG
    [23] VEC
    [21] ETH_PCIE — OR of all ETH_PCIe L2
    [19] UART — OR of all PL011 UARTs
    [17] SDHOST
    [15] PCM_I2S
    [13] SPI — OR of all SPI
    [11] I2C — OR of all I2C
    [2n+3] GPIO_{n} (n=0..3)
    [1] SMI
  0x28 GICD_ICFGR40 — Interrupt Configuration 160 - 175
    [all] fields
      0=LEVEL (Level sensitive); 1=EDGE (Edge triggered)
    [2n-319] INT{n} (n=160..175) — Interrupt {n}
  0x2C GICD_ICFGR44 — Interrupt Configuration 176 - 191
    [all] fields
      0=LEVEL (Level sensitive); 1=EDGE (Edge triggered)
    [2n-351] INT{n} (n=176..191) — Interrupt {n}
  0x30 GICD_ICFGR48 — Interrupt Configuration 192 - 207
    [all] fields
      0=LEVEL (Level sensitive); 1=EDGE (Edge triggered)
    [2n-383] INT{n} (n=192..207) — Interrupt {n}
  0x34 GICD_ICFGR52 — Interrupt Configuration 208 - 223
    [all] fields
      0=LEVEL (Level sensitive); 1=EDGE (Edge triggered)
    [2n-415] INT{n} (n=208..223) — Interrupt {n}
0xD00 GICD_PPISR — Private Peripheral Interrupt Status Register
  [15] ID31 — nLEGACYIRQ signal
  [14] ID30 — Non-secure physical timer event
  [13] ID29 — Secure physical timer event
  [12] ID28 — nLEGACYFIQ signal
  [11] ID27 — Virtual timer event
  [10] ID26 — Hypervisor timer event
  [9] ID25 — Virtual maintenance interrupt
0xD04 GICD_SPISR0 — Shared Peripheral Interrupt Status Registers
  [n-32] SPI{n} (n=32..63) — Shared interrupt {n}
0xD08 GICD_SPISR1 — Shared Peripheral Interrupt Status Registers
  [n-64] SPI{n} (n=80..95) — Shared interrupt {n}
  [n+8] SWI{n} (n=0..7) — Software interrupt {n}
  [7] ARM_AXI_ERROR
  [6] ARM_ADDRESS_ERROR
  [5] VPU1_HALTED
  [4] VPU0_HALTED
  [3] DOORBELL1
  [2] DOORBELL0
  [1] MAILBOX
  [0] TIMER — ARMC Timer
0xD0C GICD_SPISR2 — Shared Peripheral Interrupt Status Registers
  fields as GICD_IGROUPR.GICD_IGROUPR3
0xD10 GICD_SPISR3 — Shared Peripheral Interrupt Status Registers
  fields as GICD_IGROUPR.GICD_IGROUPR4
0xD14 GICD_SPISR4 — Shared Peripheral Interrupt Status Registers
  [n-160] SPI{n} (n=160..191) — Shared interrupt {n}
0xD18 GICD_SPISR5 — Shared Peripheral Interrupt Status Registers
  [n-192] SPI{n} (n=192..223) — Shared interrupt {n}
0xF00 GICD_SGIR wo reset not defined — Software Generated Interrupt Register
0xF10 GICD_CPENDSGIRn — SGI Clear-Pending Registers
0xF20 GICD_SPENDSGIRn — SGI Set-Pending Registers
0xFD0 GICD_PIDR4 ro reset 0x4 — Peripheral ID 4
  [31:0] GICD_PIDR4
    4=VALID; other=INVALID
{0xFC0+4i} GICD_PIDR{i} ro (i=5..7) — Peripheral ID {i}
  [31:0] GICD_PIDR{i}
    0=VALID; other=INVALID
0xFE0 GICD_PIDR0 ro reset 0x90 — Peripheral ID 0
  [31:0] GICD_PIDR0
    144=VALID; other=INVALID
0xFE4 GICD_PIDR1 ro reset 0xB4 — Peripheral ID 1
  [31:0] GICD_PIDR1
    180=VALID; other=INVALID
0xFE8 GICD_PIDR2 ro reset 0x2B — Peripheral ID 2
  [31:0] GICD_PIDR2
    43=VALID; other=INVALID
0xFEC GICD_PIDR3 ro — Peripheral ID 3
  [31:0] GICD_PIDR3
    0=VALID; other=INVALID
0xFF0 GICD_CIDR0 ro reset 0xD — Component ID 0
  [31:0] GICD_CIDR0
    13=VALID; other=INVALID (Invalid ID)
0xFF4 GICD_CIDR1 ro reset 0xF0 — Component ID 1
  [31:0] GICD_CIDR1
    240=VALID; other=INVALID (Invalid ID)
0xFF8 GICD_CIDR2 ro reset 0x5 — Component ID 2
  [31:0] GICD_CIDR2
    5=VALID; other=INVALID (Invalid ID)
0xFFC GICD_CIDR3 ro reset 0xB1 — Component ID 3
  [31:0] GICD_CIDR3
    177=VALID; other=INVALID (Invalid ID)
